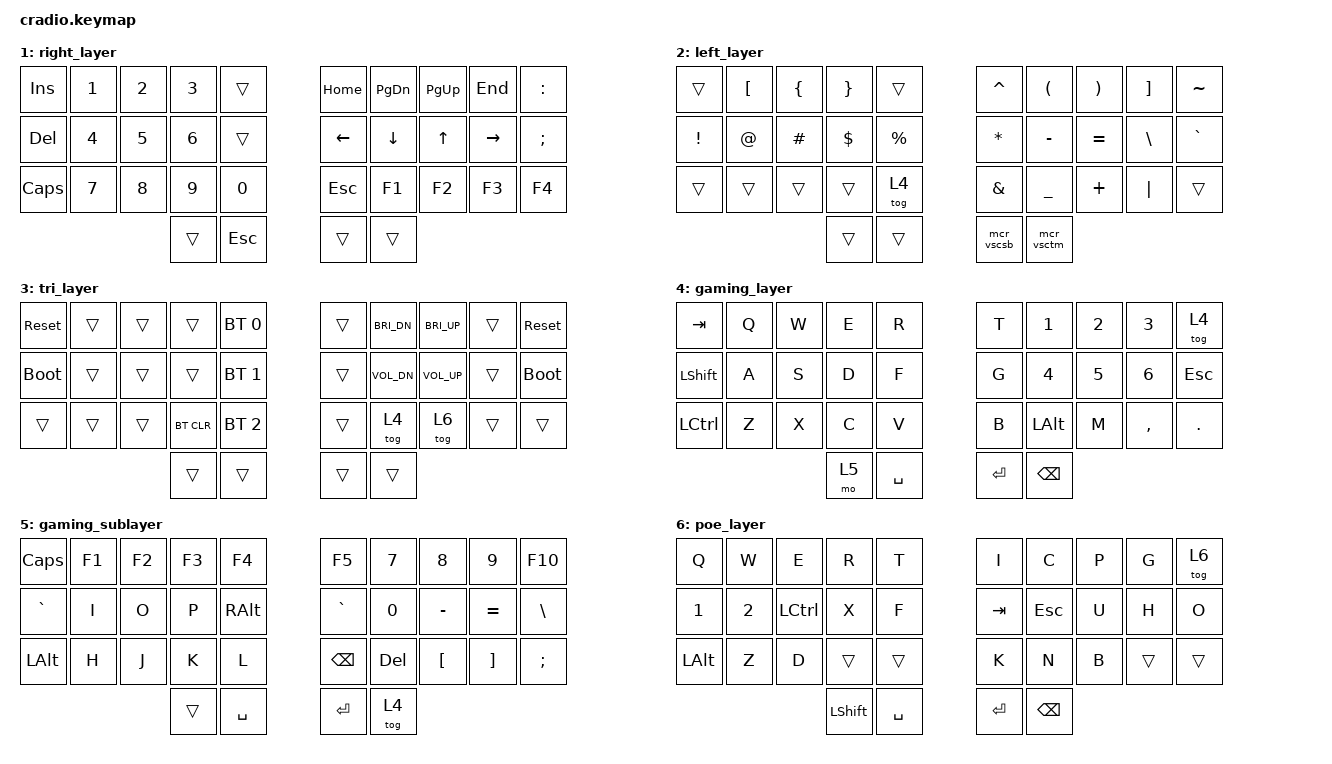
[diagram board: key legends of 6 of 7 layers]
// Copyright (c) 2022 The ZMK Contributors
// SPDX-License-Identifier: MIT

#include <behaviors.dtsi>
#include <dt-bindings/zmk/keys.h>
#include <dt-bindings/zmk/bt.h>

// Home row mods macro
#define HRML(k1,k2,k3,k4) &ht LSHFT k1  &ht LALT k2  &ht LCTRL k3  &ht LGUI k4
// Modified right home row mods - removed mod from index finger (J key)
#define HRMR(k1,k2,k3) &kp k1  &ht RCTRL k2  &ht RALT k3  &ht RSHFT SQT

#define STRINGIFY(x) #x
#define EXPAND_AND_STRINGIFY(x) STRINGIFY(x)
#define MACRO(NAME, BINDINGS) \
  mcr_##NAME: mcr_##NAME { \
    label = EXPAND_AND_STRINGIFY(mcr_##NAME); \
    compatible = "zmk,behavior-macro"; \
    #binding-cells = <0>; \
    wait-ms = <20>; \
    tap-ms = <10>; \
    bindings = <BINDINGS>; \
  };

&lt {
    quick-tap-ms = <175>;
};

/ {
    macros {
        MACRO(vscsb, &kp LC(B))
        MACRO(vsctm, &kp LC(GRAVE))
    };
};

/ {
    behaviors {
        ht: hold_tap {
            compatible = "zmk,behavior-hold-tap";
            #binding-cells = <2>;
            flavor = "tap-preferred";
            tapping-term-ms = <220>;
            quick-tap-ms = <150>;
            require-prior-idle-ms = <100>;
            bindings = <&kp>, <&kp>;
        };
    };

    conditional_layers {
        compatible = "zmk,conditional-layers";
        tri_layer {
            if-layers = <1 2>;
            then-layer = <3>;
        };
    };

    keymap {
        compatible = "zmk,keymap";
        default_layer {
            bindings = <
        //╭──────────┬──────────┬──────────┬──────────┬──────────╮   ╭──────────┬──────────┬──────────┬──────────┬──────────╮
        //│  Q       │  W       │  E       │  R       │  T       │   │  Y       │  U       │  I       │  O       │  P       │
            &kp Q      &kp W      &kp E      &kp R      &kp T          &kp Y      &kp U      &kp I      &kp O      &kp P
        //├──────────┼──────────┼──────────┼──────────┼──────────┤   ├──────────┼──────────┼──────────┼──────────┼──────────┤
        //│  A       │  S       │  D       │  F       │  G       │   │  H       │  J       │  K       │  L       │ ' "      │
            HRML(A,        S,         D,         F)     &kp G          &kp H      HRMR(J,        K,         L)
        //├──────────┼──────────┼──────────┼──────────┼──────────┤   ├──────────┼──────────┼──────────┼──────────┼──────────┤
        //│  Z       │  X       │  C       │  V       │  B       │   │  N       │  M       │ , <      │ . >      │ / ?      │
            &kp Z      &kp X      &kp C      &kp V      &kp B          &kp N      &kp M      &kp COMMA  &kp DOT    &kp FSLH
        //╰──────────┴──────────┴──────────┼──────────┼──────────┤   ├──────────┼──────────┼──────────┴──────────┴──────────╯
                                            &lt 2 TAB   &kp SPACE     &kp ENTER  &lt 1 BSPC
        //                                 ╰──────────┴──────────╯   ╰──────────┴──────────╯
            >;
        };

        right_layer {
            bindings = <
        //╭──────────┬──────────┬──────────┬──────────┬──────────╮   ╭──────────┬──────────┬──────────┬──────────┬──────────╮
        //│ INSERT   │  1       │  2       │  3       │          │   │ HOME     │ PAGE DN  │ PAGE UP  │ END      │  :       │
            &kp INS    &kp N1     &kp N2     &kp N3     &trans         &kp HOME   &kp PG_DN  &kp PG_UP  &kp END    &kp COLON
        //├──────────┼──────────┼──────────┼──────────┼──────────┤   ├──────────┼──────────┼──────────┼──────────┼──────────┤
        //│ DELETE   │  4       │  5       │  6       │          │   │ LEFT     │ DOWN     │ UP       │ RIGHT    │  ;       │
            &kp DEL    &kp N4     &kp N5     &kp N6     &trans         &kp LEFT   &kp DOWN   &kp UP   &kp RIGHT   &kp SEMI
        //├──────────┼──────────┼──────────┼──────────┼──────────┤   ├──────────┼──────────┼──────────┼──────────┼──────────┤
        //│ CAPS     │  7       │  8       │  9       │  0       │   │ ESC      │ F1       │  F2      │  F3      │  F4      │
            &kp CAPS   &kp N7     &kp N8     &kp N9     &kp N0        &kp ESC     &kp F1     &kp F2     &kp F3     &kp F4
        //╰──────────┴──────────┴──────────┼──────────┼──────────┤   ├──────────┼──────────┼──────────┴──────────┴──────────╯
                                             &trans     &kp ESC        &trans     &trans
        //                                 ╰──────────┴──────────╯   ╰──────────┴──────────╯
            >;
        };

        left_layer {
            bindings = <
        //╭──────────┬──────────┬──────────┬──────────┬──────────╮   ╭──────────┬──────────┬──────────┬──────────┬──────────╮
        //│          │  [       │  {       │  }       │          │   │  ^       │  (       │  )       │  ]       │  ~       │
            &trans     &kp LBKT   &kp LBRC   &kp RBRC   &trans         &kp CARET  &kp LPAR   &kp RPAR   &kp RBKT   &kp TILDE
        //├──────────┼──────────┼──────────┼──────────┼──────────┤   ├──────────┼──────────┼──────────┼──────────┼──────────┤
        //│  !       │  @       │  #       │  $       │  %       │   │  *       │  -       │  =       │  \       │  `       │
            &kp EXCL   &kp AT     &kp HASH   &kp DLLR   &kp PRCNT      &kp ASTRK  &kp MINUS  &kp EQUAL  &kp BSLH   &kp GRAVE
        //├──────────┼──────────┼──────────┼──────────┼──────────┤   ├──────────┼──────────┼──────────┼──────────┼──────────┤
        //│          │          │          │          │GAME MODE │   │  &       │  _       │  +       │  │       │          │
            &trans     &trans     &trans     &trans     &tog 4         &kp AMPS   &kp UNDER  &kp PLUS   &kp PIPE   &trans
        //╰──────────┴──────────┴──────────┼──────────┼──────────┤   ├──────────┼──────────┼──────────┴──────────┴──────────╯
                                             &trans     &trans        &mcr_vscsb &mcr_vsctm
        //                                 ╰──────────┴──────────╯   ╰──────────┴──────────╯
            >;
        };

        tri_layer {
            bindings = <
        //╭──────────┬──────────┬──────────┬──────────┬──────────╮   ╭──────────┬──────────┬──────────┬──────────┬──────────╮
        //│ RESET    │          │          │          │PROFILE 0 │   │          │Brtnss dn │Brtnss up │          │  RESET   │
           &sys_reset  &trans     &trans     &trans    &bt BT_SEL 0    &trans   &kp C_BRI_DN &kp C_BRI_UP &trans  &sys_reset
        //├──────────┼──────────┼──────────┼──────────┼──────────┤   ├──────────┼──────────┼──────────┼──────────┼──────────┤
        //│BOOTLOADER│          │          │          │PROFILE 1 │   │          │Volume dn │Volume up │          │BOOTLOADER│
          &bootloader  &trans     &trans     &trans    &bt BT_SEL 1    &trans   &kp C_VOL_DN &kp C_VOL_UP &trans  &bootloader
        //├──────────┼──────────┼──────────┼──────────┼──────────┤   ├──────────┼──────────┼──────────┼──────────┼──────────┤
        //│          │          │          │ CLEAR BT │PROFILE 2 │   │          │GAME MODE │ POE MODE │          │          │
            &trans     &trans     &trans    &bt BT_CLR &bt BT_SEL 2    &trans     &tog 4     &tog 6     &trans     &trans
        //╰──────────┴──────────┴──────────┼──────────┼──────────┤   ├──────────┼──────────┼──────────┴──────────┴──────────╯
                                             &trans     &trans         &trans     &trans
        //                                 ╰──────────┴──────────╯   ╰──────────┴──────────╯
            >;
        };

        gaming_layer {
            bindings = <
        //╭──────────┬──────────┬──────────┬──────────┬──────────╮   ╭──────────┬──────────┬──────────┬──────────┬──────────╮
        //│  Tab     │  Q       │  W       │  E       │  R       │   │  T       │  1       │  2       │  3       │  EXIT    │
            &kp TAB    &kp Q      &kp W      &kp E      &kp R          &kp T      &kp N1     &kp N2     &kp N3     &tog 4
        //├──────────┼──────────┼──────────┼──────────┼──────────┤   ├──────────┼──────────┼──────────┼──────────┼──────────┤
        //│  Shift   │  A       │  S       │  D       │  F       │   │  G       │  4       │  5       │  6       │  ESC     │
            &kp LSHFT  &kp A      &kp S      &kp D      &kp F          &kp G      &kp N4     &kp N5     &kp N6     &kp ESC
        //├──────────┼──────────┼──────────┼──────────┼──────────┤   ├──────────┼──────────┼──────────┼──────────┼──────────┤
        //│  Ctrl    │  Z       │  X       │  C       │  V       │   │  B       │  LALT    │  M       │ , <      │ . >      │
            &kp LCTRL  &kp Z      &kp X      &kp C      &kp V          &kp B      &kp LALT   &kp M      &kp COMMA  &kp DOT
        //╰──────────┴──────────┴──────────┼──────────┼──────────┤   ├──────────┼──────────┼──────────┴──────────┴──────────╯
                                             &mo 5      &kp SPACE      &kp ENTER  &kp BSPC
        //                                 ╰──────────┴──────────╯   ╰──────────┴──────────╯
            >;
        };

        gaming_sublayer {
            bindings = <
        //╭──────────┬──────────┬──────────┬──────────┬──────────╮   ╭──────────┬──────────┬──────────┬──────────┬──────────╮
        //│  CAPS    │  F1      │  F2      │  F3      │  F4      │   │  F5      │  7       │  8       │  9       │  F10     │
            &kp CAPS   &kp F1     &kp F2     &kp F3     &kp F4         &kp F5     &kp N7     &kp N8     &kp N9     &kp F10
        //├──────────┼──────────┼──────────┼──────────┼──────────┤   ├──────────┼──────────┼──────────┼──────────┼──────────┤
        //│  `       │  I       │  O       │  P       │  RALT    │   │ GRAVE    │  0       │  -       │  =       │  \       │
            &kp GRAVE  &kp I      &kp O      &kp P      &kp RALT       &kp GRAVE  &kp N0     &kp MINUS  &kp EQUAL  &kp BSLH
        //├──────────┼──────────┼──────────┼──────────┼──────────┤   ├──────────┼──────────┼──────────┼──────────┼──────────┤
        //│  LALT    │  H       │  J       │  K       │  L       │   │ BSPC     │  DEL     │  [       │  ]       │  ;       │
            &kp LALT   &kp H      &kp J      &kp K      &kp L          &kp BSPC   &kp DEL    &kp LBKT   &kp RBKT   &kp SEMI
        //╰──────────┴──────────┴──────────┼──────────┼──────────┤   ├──────────┼──────────┼──────────┴──────────┴──────────╯
                                             &trans     &kp SPACE      &kp ENTER  &tog 4
        //                                 ╰──────────┴──────────╯   ╰──────────┴──────────╯
            >;
        };

        poe_layer {
            bindings = <
        //╭──────────┬──────────┬──────────┬──────────┬──────────╮   ╭──────────┬──────────┬──────────┬──────────┬──────────╮
        //│  Q       │  W       │  E       │  R       │  T       │   │  Invntry │  Char    │  Passive │  Gems    │  EXIT    │
            &kp Q      &kp W      &kp E      &kp R      &kp T          &kp I      &kp C      &kp P      &kp G      &tog 6
        //├──────────┼──────────┼──────────┼──────────┼──────────┤   ├──────────┼──────────┼──────────┼──────────┼──────────┤
        //│  Flask 1 │  Flask 2 │  Ctrl    │  WpnSwap │  Pickup  │   │  Map     │  Esc     │  World   │  Chalng  │  Options │
            &kp N1     &kp N2     &kp LCTRL  &kp X      &kp F          &kp TAB    &kp ESC    &kp U      &kp H      &kp O
        //├──────────┼──────────┼──────────┼──────────┼──────────┤   ├──────────┼──────────┼──────────┼──────────┼──────────┤
        //│  Hilite  │  TogHilt │  Detonat │          │          │   │  Cosmtc  │  MtxLst  │  Events  │          │          │
            &kp LALT   &kp Z      &kp D      &trans     &trans         &kp K      &kp N      &kp B      &trans     &trans
        //╰──────────┴──────────┴──────────┼──────────┼──────────┤   ├──────────┼──────────┼──────────┴──────────┴──────────╯
                                             &kp LSHFT  &kp SPACE      &kp ENTER  &kp BSPC
        //                                 ╰─AtkPlace─┴──Dodge──╯   ╰──Chat────┴──BSPC───╯
            >;
        };
    };
};
